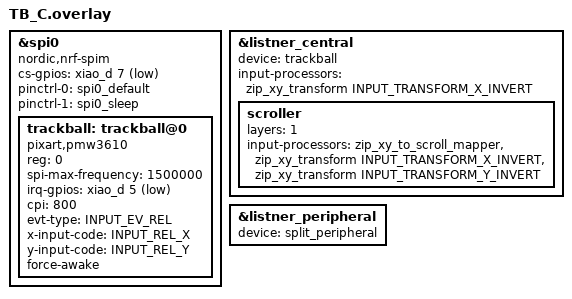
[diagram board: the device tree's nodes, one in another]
#include <input/processors.dtsi>
#include <zephyr/dt-bindings/input/input-event-codes.h>
#include "TB_pinctrl.dtsi"
#include "Listners.dtsi"

&spi0 {
    status = "okay";
    cs-gpios =  <&xiao_d 7 GPIO_ACTIVE_LOW>;
    pinctrl-0 = <&spi0_default>;
    pinctrl-1 = <&spi0_sleep>;
    pinctrl-names = "default", "sleep";
    compatible = "nordic,nrf-spim";

    trackball: trackball@0 {
        status = "okay";
        compatible = "pixart,pmw3610";
        reg = <0>;
        spi-max-frequency = <1500000>;
        irq-gpios = <&xiao_d 5 (GPIO_ACTIVE_LOW | GPIO_PULL_UP)>;
        cpi = <800>;
        evt-type = <INPUT_EV_REL>;
        x-input-code = <INPUT_REL_X>;
        y-input-code = <INPUT_REL_Y>;
        force-awake;
    };
};

&listner_central{
    device = <&trackball>;
    status = "okay";
    input-processors = <&zip_xy_transform INPUT_TRANSFORM_X_INVERT>;

    scroller {
        layers = <1>;
        input-processors
        = <&zip_xy_to_scroll_mapper>
        , <&zip_xy_transform INPUT_TRANSFORM_X_INVERT>
        , <&zip_xy_transform INPUT_TRANSFORM_Y_INVERT>
        ;
    };
};

&listner_peripheral{
    device = <&split_peripheral>;
    status = "okay";
    // input-processors = <&zip_xy_transform INPUT_TRANSFORM_X_INVERT>, <&zip_xy_scaler 1 2>, <&zip_xy_to_scroll_mapper>;
};
